AUTOSAR XML (schema 4-2-1)
package /Application_Data_Types
  base type uint8_Base_t: category=FIXED_LENGTH, base-type-size=8, base-type-encoding=NONE, native-declaration=unsigned char
  impl type Door_State_t: category=VALUE, base-type=uint8_Base_t, range phys 0..255, raw 0..255
  impl type LED_State_t: category=VALUE, base-type=uint8_Base_t, range phys 0..255, raw 0..255
package /Interfaces
  sender receiver interface Sender_Receiver_Interface_Door_Sensor
    data Current_State: type=Door_State_t
  client server interface Client_Server_Interface_Control_LED
    operation Set_LED_State: possible-error=[E_OK, E_NOT_OK]
      arg LED_State: type=LED_State_t, direction=IN
    error E_OK: error-code=0
    error E_NOT_OK: error-code=1
package /SWCs
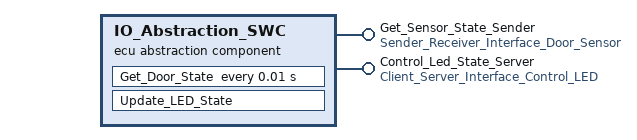
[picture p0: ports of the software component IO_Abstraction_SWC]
  ecu abstraction sw component type IO_Abstraction_SWC
    provide port Get_Sensor_State_Sender: provided-interface=Sender_Receiver_Interface_Door_Sensor
    provide port Control_Led_State_Server: provided-interface=Client_Server_Interface_Control_LED
    behavior Internel_Behavior_IO_Abstraction_SWC
      timing event Get_Door_State_Timing_Event_1ms: start-on-event=Get_Door_State, period=0.01
      operation invoked event Get_Door_State_Operation_Invoked_Event: start-on-event=Update_LED_State, operation=Control_Led_State_Server.Set_LED_State
      runnable Get_Door_State: symbol=Get_Door_State_Runnable
        data-write-access:
          access Door_State_Data_Write_Access: accessed-variable=Get_Sensor_State_Sender.Current_State
      runnable Update_LED_State: symbol=Update_LED_State_Runnable
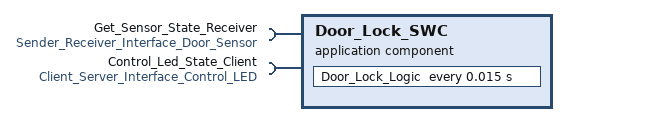
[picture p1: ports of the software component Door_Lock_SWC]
  application sw component type Door_Lock_SWC
    require port Get_Sensor_State_Receiver: required-interface=Sender_Receiver_Interface_Door_Sensor
    require port Control_Led_State_Client: required-interface=Client_Server_Interface_Control_LED
    behavior Internel_Behavior_Door_Lock_SWC
      timing event Timing_Event_15ms: start-on-event=Door_Lock_Logic, period=0.015
      runnable Door_Lock_Logic: symbol=Door_Lock_Logic_Runnable
        data-read-access:
          access Door_State_Data_Read_Access: accessed-variable={autosar-variable=Get_Sensor_State_Receiver.Current_State, local-variable=Current_State}
        sync call LED_State_Server_Call: operation=Control_Led_State_Client.Set_LED_State
package /Composition
  composition sw component type Composite_Application_SWC
    component IO_Abstraction_SWC: type=IO_Abstraction_SWC
    component Door_Lock_SWC: type=Door_Lock_SWC
    connect IO_Abstraction_SWC.Control_Led_State_Server -> Door_Lock_SWC.Control_Led_State_Client
    connect IO_Abstraction_SWC.Get_Sensor_State_Sender -> Door_Lock_SWC.Get_Sensor_State_Receiver
